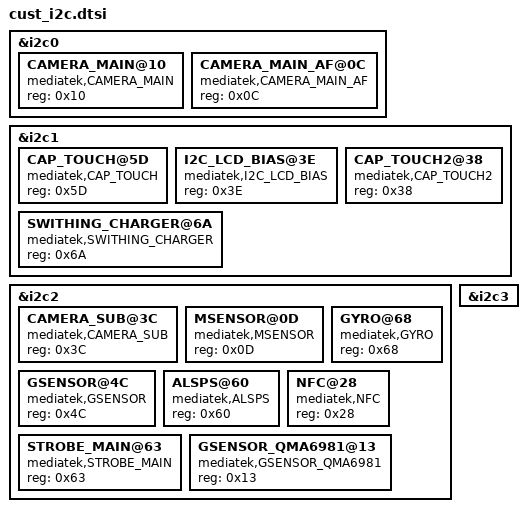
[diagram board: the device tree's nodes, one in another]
/*
 * Generated by MTK SP DrvGen Version 03.13.6 for MT6735M. Copyright MediaTek Inc. (C) 2013.
 * Fri Sep 09 14:36:15 2016
 * Do Not Modify the File.
 */

/*************************
 * I2C DTSI File
*************************/

&i2c0 {
	CAMERA_MAIN@10 {
		compatible = "mediatek,CAMERA_MAIN";
		reg = <0x10>;
	};

	CAMERA_MAIN_AF@0C {
		compatible = "mediatek,CAMERA_MAIN_AF";
		reg = <0x0C>;
	};

};

&i2c1 {
	CAP_TOUCH@5D {
		compatible = "mediatek,CAP_TOUCH";
		reg = <0x5D>;
	};

	I2C_LCD_BIAS@3E {
		compatible = "mediatek,I2C_LCD_BIAS";
		reg = <0x3E>;
	};

	SWITHING_CHARGER@6A {
		compatible = "mediatek,SWITHING_CHARGER";
		reg = <0x6A>;
	};

	CAP_TOUCH2@38 {
		compatible = "mediatek,CAP_TOUCH2";
		reg = <0x38>;
	};

};

&i2c2 {
	CAMERA_SUB@3C {
		compatible = "mediatek,CAMERA_SUB";
		reg = <0x3C>;
	};

	MSENSOR@0D {
		compatible = "mediatek,MSENSOR";
		reg = <0x0D>;
	};

	GYRO@68 {
		compatible = "mediatek,GYRO";
		reg = <0x68>;
	};

	GSENSOR@4C {
		compatible = "mediatek,GSENSOR";
		reg = <0x4C>;
	};

	ALSPS@60 {
		compatible = "mediatek,ALSPS";
		reg = <0x60>;
	};

	NFC@28 {
		compatible = "mediatek,NFC";
		reg = <0x28>;
	};

	STROBE_MAIN@63 {
		compatible = "mediatek,STROBE_MAIN";
		reg = <0x63>;
	};

	GSENSOR_QMA6981@13 {
		compatible = "mediatek,GSENSOR_QMA6981";
		reg = <0x13>;
	};

};

&i2c3 {
};

